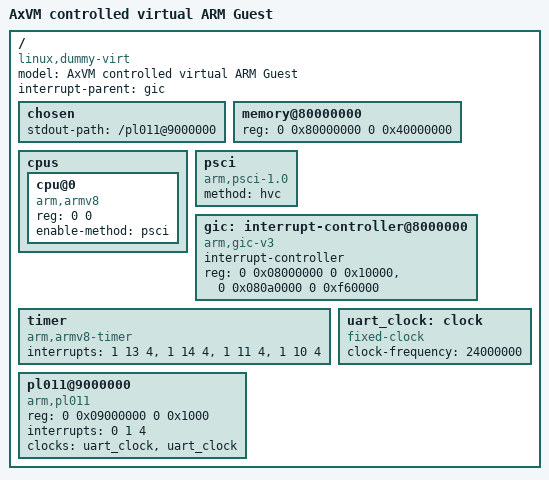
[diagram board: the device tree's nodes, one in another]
/dts-v1/;

/ {
    #address-cells = <2>;
    #size-cells = <2>;
    compatible = "linux,dummy-virt";
    model = "AxVM controlled virtual ARM Guest";
    interrupt-parent = <&gic>;

    chosen { stdout-path = "/pl011@9000000"; };
    memory@80000000 {
        device_type = "memory";
        reg = <0 0x80000000 0 0x40000000>;
    };
    cpus {
        #address-cells = <2>;
        #size-cells = <0>;
        cpu@0 {
            device_type = "cpu";
            compatible = "arm,armv8";
            reg = <0 0>;
            enable-method = "psci";
        };
    };
    psci { compatible = "arm,psci-1.0"; method = "hvc"; };
    gic: interrupt-controller@8000000 {
        compatible = "arm,gic-v3";
        #interrupt-cells = <3>;
        #address-cells = <2>;
        #size-cells = <2>;
        ranges;
        interrupt-controller;
        reg = <0 0x08000000 0 0x10000>, <0 0x080a0000 0 0xf60000>;
    };
    timer {
        compatible = "arm,armv8-timer";
        interrupts = <1 13 4>, <1 14 4>, <1 11 4>, <1 10 4>;
    };
    uart_clock: clock {
        compatible = "fixed-clock";
        #clock-cells = <0>;
        clock-frequency = <24000000>;
    };
    pl011@9000000 {
        compatible = "arm,pl011", "arm,primecell";
        reg = <0 0x09000000 0 0x1000>;
        interrupts = <0 1 4>;
        clocks = <&uart_clock>, <&uart_clock>;
        clock-names = "uartclk", "apb_pclk";
    };
};
